# VPAC0_PAR_VPAC_VISS0_S_VBUSP_KSDW_ECC_AGGR_CFG register map
Vendor: Texas Instruments
Peripheral module from a debugger description file (folder J7ES).
Registers are 32-bit, access not given, reset 0x0 unless marked. A register's access mark holds for its fields unless they carry their own. Offsets are as the file gives them; lines under a group give offsets from that group; [hi:lo] are bit positions; {n}, {i} and the like mark numbered series; 'fields as' and 'values as' point back to an identical list; <NAME> marks a mode.

## VPAC0_PAR_VPAC_VISS0_S_VBUSP_KSDW_ECC_AGGR_CFG
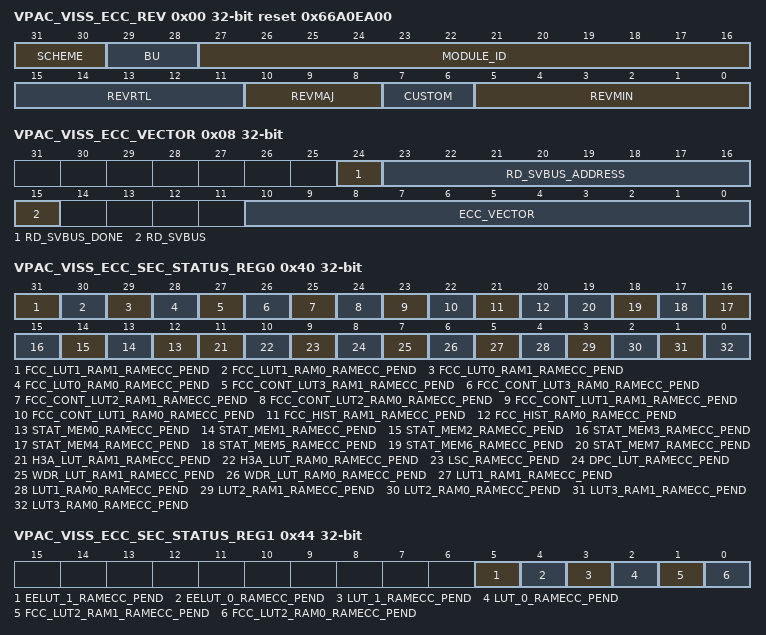
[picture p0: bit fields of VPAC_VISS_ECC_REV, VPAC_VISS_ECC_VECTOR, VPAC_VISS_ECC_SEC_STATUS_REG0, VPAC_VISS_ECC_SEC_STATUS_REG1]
0x00 VPAC_VISS_ECC_REV ro reset 0x66A0EA00 — Revision parameters
  [31:30] SCHEME
  [29:28] BU
  [27:16] MODULE_ID
  [15:11] REVRTL — RTL version
  [10:8] REVMAJ — Major version
  [7:6] CUSTOM — Custom version
  [5:0] REVMIN — Minor version
0x08 VPAC_VISS_ECC_VECTOR — ECC Register
  [24] RD_SVBUS_DONE — Status to indicate if read on serial VBUS is complete, write of any value will clear this bit. (access RW1C)
  [23:16] RD_SVBUS_ADDRESS rw — Read address
  [15] RD_SVBUS — Write 1 to trigger a read on the serial VBUS (access RW1S)
  [10:0] ECC_VECTOR rw — Value written to select the corresponding ECC RAM for control or status
0x0C VPAC_VISS_ECC_STAT ro reset 0x26 — Misc Status
  [10:0] NUM_RAMS — Indicates the number of RAMS serviced by the ECC aggregator
0x10 VPAC_VISS_ECC_RESERVED_SVBUS_y rw — Reference other documents that contain the ECC RAM wrapper and EDC controller serial vbus register sets. Offset = 1010h + (y * 4h); where y = 0h to 7h
  [31:0] DATA — Serial VBUS register data
0x3C VPAC_VISS_ECC_SEC_EOI_REG — EOI Register The EOI register is used to re-trigger the pulse interrupt signal to ensure that any nested interrupt events are serviced. The software interrupt handler must write to the EOI register at the end of the current interrupt processing routine, so that new events can re-trigger the pulse interrupt signal again. For level interrupt signals the EOI register is not functional and must not be used.
  [0] EOI_WR — EOI Register (access RW1S)
0x40 VPAC_VISS_ECC_SEC_STATUS_REG0 — Interrupt Status Register 0
  [31] FCC_LUT1_RAM1_RAMECC_PEND — Interrupt Pending Status for fcc_lut1_ram1_ramecc_pend (access RW1S)
  [30] FCC_LUT1_RAM0_RAMECC_PEND — Interrupt Pending Status for fcc_lut1_ram0_ramecc_pend (access RW1S)
  [29] FCC_LUT0_RAM1_RAMECC_PEND — Interrupt Pending Status for fcc_lut0_ram1_ramecc_pend (access RW1S)
  [28] FCC_LUT0_RAM0_RAMECC_PEND — Interrupt Pending Status for fcc_lut0_ram0_ramecc_pend (access RW1S)
  [27] FCC_CONT_LUT3_RAM1_RAMECC_PEND — Interrupt Pending Status for fcc_cont_lut3_ram1_ramecc_pend (access RW1S)
  [26] FCC_CONT_LUT3_RAM0_RAMECC_PEND — Interrupt Pending Status for fcc_cont_lut3_ram0_ramecc_pend (access RW1S)
  [25] FCC_CONT_LUT2_RAM1_RAMECC_PEND — Interrupt Pending Status for fcc_cont_lut2_ram1_ramecc_pend (access RW1S)
  [24] FCC_CONT_LUT2_RAM0_RAMECC_PEND — Interrupt Pending Status for fcc_cont_lut2_ram0_ramecc_pend (access RW1S)
  [23] FCC_CONT_LUT1_RAM1_RAMECC_PEND — Interrupt Pending Status for fcc_cont_lut1_ram1_ramecc_pend (access RW1S)
  [22] FCC_CONT_LUT1_RAM0_RAMECC_PEND — Interrupt Pending Status for fcc_cont_lut1_ram0_ramecc_pend (access RW1S)
  [21] FCC_HIST_RAM1_RAMECC_PEND — Interrupt Pending Status for fcc_hist_ram1_ramecc_pend (access RW1S)
  [20] FCC_HIST_RAM0_RAMECC_PEND — Interrupt Pending Status for fcc_hist_ram0_ramecc_pend (access RW1S)
  [n+12] STAT_MEM{n}_RAMECC_PEND (n=0..7) — Interrupt Pending Status for stat_mem{n}_ramecc_pend (access RW1S)
  [11] H3A_LUT_RAM1_RAMECC_PEND — Interrupt Pending Status for h3a_lut_ram1_ramecc_pend (access RW1S)
  [10] H3A_LUT_RAM0_RAMECC_PEND — Interrupt Pending Status for h3a_lut_ram0_ramecc_pend (access RW1S)
  [9] LSC_RAMECC_PEND — Interrupt Pending Status for lsc_ramecc_pend (access RW1S)
  [8] DPC_LUT_RAMECC_PEND — Interrupt Pending Status for dpc_lut_ramecc_pend (access RW1S)
  [7] WDR_LUT_RAM1_RAMECC_PEND — Interrupt Pending Status for wdr_lut_ram1_ramecc_pend (access RW1S)
  [6] WDR_LUT_RAM0_RAMECC_PEND — Interrupt Pending Status for wdr_lut_ram0_ramecc_pend (access RW1S)
  [5] LUT1_RAM1_RAMECC_PEND — Interrupt Pending Status for lut1_ram1_ramecc_pend (access RW1S)
  [4] LUT1_RAM0_RAMECC_PEND — Interrupt Pending Status for lut1_ram0_ramecc_pend (access RW1S)
  [3] LUT2_RAM1_RAMECC_PEND — Interrupt Pending Status for lut2_ram1_ramecc_pend (access RW1S)
  [2] LUT2_RAM0_RAMECC_PEND — Interrupt Pending Status for lut2_ram0_ramecc_pend (access RW1S)
  [1] LUT3_RAM1_RAMECC_PEND — Interrupt Pending Status for lut3_ram1_ramecc_pend (access RW1S)
  [0] LUT3_RAM0_RAMECC_PEND — Interrupt Pending Status for lut3_ram0_ramecc_pend (access RW1S)
0x44 VPAC_VISS_ECC_SEC_STATUS_REG1 — Interrupt Status Register 1
  [5] EELUT_1_RAMECC_PEND — Interrupt Pending Status for eelut_1_ramecc_pend (access RW1S)
  [4] EELUT_0_RAMECC_PEND — Interrupt Pending Status for eelut_0_ramecc_pend (access RW1S)
  [3] LUT_1_RAMECC_PEND — Interrupt Pending Status for lut_1_ramecc_pend (access RW1S)
  [2] LUT_0_RAMECC_PEND — Interrupt Pending Status for lut_0_ramecc_pend (access RW1S)
  [1] FCC_LUT2_RAM1_RAMECC_PEND — Interrupt Pending Status for fcc_lut2_ram1_ramecc_pend (access RW1S)
  [0] FCC_LUT2_RAM0_RAMECC_PEND — Interrupt Pending Status for fcc_lut2_ram0_ramecc_pend (access RW1S)
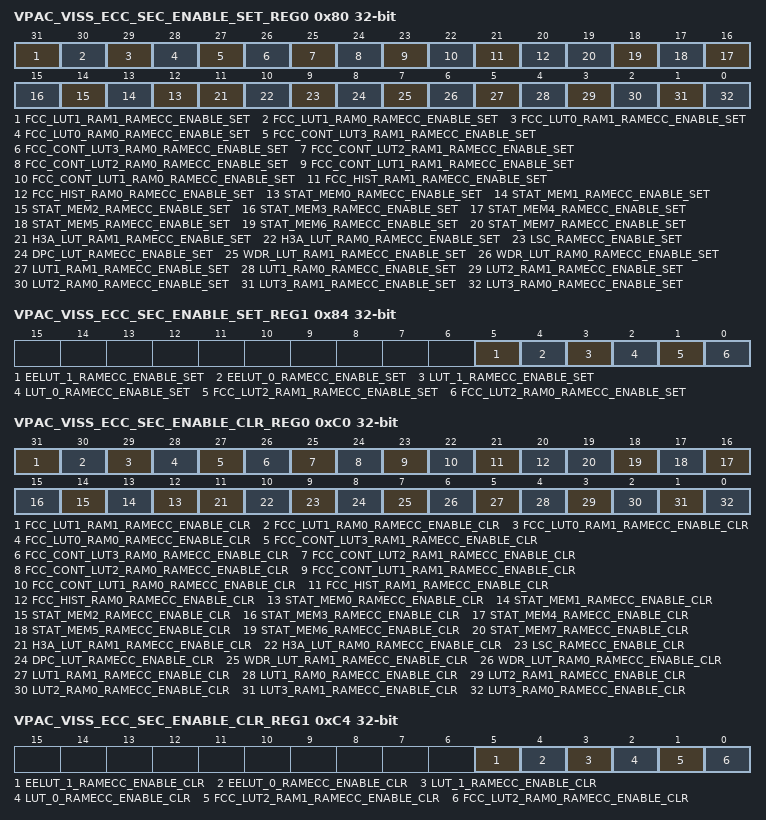
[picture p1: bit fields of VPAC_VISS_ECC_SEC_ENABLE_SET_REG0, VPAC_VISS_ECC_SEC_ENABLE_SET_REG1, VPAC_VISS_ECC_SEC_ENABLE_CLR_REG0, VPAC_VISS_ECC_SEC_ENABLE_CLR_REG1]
0x80 VPAC_VISS_ECC_SEC_ENABLE_SET_REG0 — Interrupt Enable Set Register 0
  [31] FCC_LUT1_RAM1_RAMECC_ENABLE_SET — Interrupt Enable Set Register for fcc_lut1_ram1_ramecc_pend (access RW1S)
  [30] FCC_LUT1_RAM0_RAMECC_ENABLE_SET — Interrupt Enable Set Register for fcc_lut1_ram0_ramecc_pend (access RW1S)
  [29] FCC_LUT0_RAM1_RAMECC_ENABLE_SET — Interrupt Enable Set Register for fcc_lut0_ram1_ramecc_pend (access RW1S)
  [28] FCC_LUT0_RAM0_RAMECC_ENABLE_SET — Interrupt Enable Set Register for fcc_lut0_ram0_ramecc_pend (access RW1S)
  [27] FCC_CONT_LUT3_RAM1_RAMECC_ENABLE_SET — Interrupt Enable Set Register for fcc_cont_lut3_ram1_ramecc_pend (access RW1S)
  [26] FCC_CONT_LUT3_RAM0_RAMECC_ENABLE_SET — Interrupt Enable Set Register for fcc_cont_lut3_ram0_ramecc_pend (access RW1S)
  [25] FCC_CONT_LUT2_RAM1_RAMECC_ENABLE_SET — Interrupt Enable Set Register for fcc_cont_lut2_ram1_ramecc_pend (access RW1S)
  [24] FCC_CONT_LUT2_RAM0_RAMECC_ENABLE_SET — Interrupt Enable Set Register for fcc_cont_lut2_ram0_ramecc_pend (access RW1S)
  [23] FCC_CONT_LUT1_RAM1_RAMECC_ENABLE_SET — Interrupt Enable Set Register for fcc_cont_lut1_ram1_ramecc_pend (access RW1S)
  [22] FCC_CONT_LUT1_RAM0_RAMECC_ENABLE_SET — Interrupt Enable Set Register for fcc_cont_lut1_ram0_ramecc_pend (access RW1S)
  [21] FCC_HIST_RAM1_RAMECC_ENABLE_SET — Interrupt Enable Set Register for fcc_hist_ram1_ramecc_pend (access RW1S)
  [20] FCC_HIST_RAM0_RAMECC_ENABLE_SET — Interrupt Enable Set Register for fcc_hist_ram0_ramecc_pend (access RW1S)
  [n+12] STAT_MEM{n}_RAMECC_ENABLE_SET (n=0..7) — Interrupt Enable Set Register for stat_mem{n}_ramecc_pend (access RW1S)
  [11] H3A_LUT_RAM1_RAMECC_ENABLE_SET — Interrupt Enable Set Register for h3a_lut_ram1_ramecc_pend (access RW1S)
  [10] H3A_LUT_RAM0_RAMECC_ENABLE_SET — Interrupt Enable Set Register for h3a_lut_ram0_ramecc_pend (access RW1S)
  [9] LSC_RAMECC_ENABLE_SET — Interrupt Enable Set Register for lsc_ramecc_pend (access RW1S)
  [8] DPC_LUT_RAMECC_ENABLE_SET — Interrupt Enable Set Register for dpc_lut_ramecc_pend (access RW1S)
  [7] WDR_LUT_RAM1_RAMECC_ENABLE_SET — Interrupt Enable Set Register for wdr_lut_ram1_ramecc_pend (access RW1S)
  [6] WDR_LUT_RAM0_RAMECC_ENABLE_SET — Interrupt Enable Set Register for wdr_lut_ram0_ramecc_pend (access RW1S)
  [5] LUT1_RAM1_RAMECC_ENABLE_SET — Interrupt Enable Set Register for lut1_ram1_ramecc_pend (access RW1S)
  [4] LUT1_RAM0_RAMECC_ENABLE_SET — Interrupt Enable Set Register for lut1_ram0_ramecc_pend (access RW1S)
  [3] LUT2_RAM1_RAMECC_ENABLE_SET — Interrupt Enable Set Register for lut2_ram1_ramecc_pend (access RW1S)
  [2] LUT2_RAM0_RAMECC_ENABLE_SET — Interrupt Enable Set Register for lut2_ram0_ramecc_pend (access RW1S)
  [1] LUT3_RAM1_RAMECC_ENABLE_SET — Interrupt Enable Set Register for lut3_ram1_ramecc_pend (access RW1S)
  [0] LUT3_RAM0_RAMECC_ENABLE_SET — Interrupt Enable Set Register for lut3_ram0_ramecc_pend (access RW1S)
0x84 VPAC_VISS_ECC_SEC_ENABLE_SET_REG1 — Interrupt Enable Set Register 1
  [5] EELUT_1_RAMECC_ENABLE_SET — Interrupt Enable Set Register for eelut_1_ramecc_pend (access RW1S)
  [4] EELUT_0_RAMECC_ENABLE_SET — Interrupt Enable Set Register for eelut_0_ramecc_pend (access RW1S)
  [3] LUT_1_RAMECC_ENABLE_SET — Interrupt Enable Set Register for lut_1_ramecc_pend (access RW1S)
  [2] LUT_0_RAMECC_ENABLE_SET — Interrupt Enable Set Register for lut_0_ramecc_pend (access RW1S)
  [1] FCC_LUT2_RAM1_RAMECC_ENABLE_SET — Interrupt Enable Set Register for fcc_lut2_ram1_ramecc_pend (access RW1S)
  [0] FCC_LUT2_RAM0_RAMECC_ENABLE_SET — Interrupt Enable Set Register for fcc_lut2_ram0_ramecc_pend (access RW1S)
0xC0 VPAC_VISS_ECC_SEC_ENABLE_CLR_REG0 — Interrupt Enable Clear Register 0
  [31] FCC_LUT1_RAM1_RAMECC_ENABLE_CLR — Interrupt Enable Clear Register for fcc_lut1_ram1_ramecc_pend (access RW1C)
  [30] FCC_LUT1_RAM0_RAMECC_ENABLE_CLR — Interrupt Enable Clear Register for fcc_lut1_ram0_ramecc_pend (access RW1C)
  [29] FCC_LUT0_RAM1_RAMECC_ENABLE_CLR — Interrupt Enable Clear Register for fcc_lut0_ram1_ramecc_pend (access RW1C)
  [28] FCC_LUT0_RAM0_RAMECC_ENABLE_CLR — Interrupt Enable Clear Register for fcc_lut0_ram0_ramecc_pend (access RW1C)
  [27] FCC_CONT_LUT3_RAM1_RAMECC_ENABLE_CLR — Interrupt Enable Clear Register for fcc_cont_lut3_ram1_ramecc_pend (access RW1C)
  [26] FCC_CONT_LUT3_RAM0_RAMECC_ENABLE_CLR — Interrupt Enable Clear Register for fcc_cont_lut3_ram0_ramecc_pend (access RW1C)
  [25] FCC_CONT_LUT2_RAM1_RAMECC_ENABLE_CLR — Interrupt Enable Clear Register for fcc_cont_lut2_ram1_ramecc_pend (access RW1C)
  [24] FCC_CONT_LUT2_RAM0_RAMECC_ENABLE_CLR — Interrupt Enable Clear Register for fcc_cont_lut2_ram0_ramecc_pend (access RW1C)
  [23] FCC_CONT_LUT1_RAM1_RAMECC_ENABLE_CLR — Interrupt Enable Clear Register for fcc_cont_lut1_ram1_ramecc_pend (access RW1C)
  [22] FCC_CONT_LUT1_RAM0_RAMECC_ENABLE_CLR — Interrupt Enable Clear Register for fcc_cont_lut1_ram0_ramecc_pend (access RW1C)
  [21] FCC_HIST_RAM1_RAMECC_ENABLE_CLR — Interrupt Enable Clear Register for fcc_hist_ram1_ramecc_pend (access RW1C)
  [20] FCC_HIST_RAM0_RAMECC_ENABLE_CLR — Interrupt Enable Clear Register for fcc_hist_ram0_ramecc_pend (access RW1C)
  [n+12] STAT_MEM{n}_RAMECC_ENABLE_CLR (n=0..7) — Interrupt Enable Clear Register for stat_mem{n}_ramecc_pend (access RW1C)
  [11] H3A_LUT_RAM1_RAMECC_ENABLE_CLR — Interrupt Enable Clear Register for h3a_lut_ram1_ramecc_pend (access RW1C)
  [10] H3A_LUT_RAM0_RAMECC_ENABLE_CLR — Interrupt Enable Clear Register for h3a_lut_ram0_ramecc_pend (access RW1C)
  [9] LSC_RAMECC_ENABLE_CLR — Interrupt Enable Clear Register for lsc_ramecc_pend (access RW1C)
  [8] DPC_LUT_RAMECC_ENABLE_CLR — Interrupt Enable Clear Register for dpc_lut_ramecc_pend (access RW1C)
  [7] WDR_LUT_RAM1_RAMECC_ENABLE_CLR — Interrupt Enable Clear Register for wdr_lut_ram1_ramecc_pend (access RW1C)
  [6] WDR_LUT_RAM0_RAMECC_ENABLE_CLR — Interrupt Enable Clear Register for wdr_lut_ram0_ramecc_pend (access RW1C)
  [5] LUT1_RAM1_RAMECC_ENABLE_CLR — Interrupt Enable Clear Register for lut1_ram1_ramecc_pend (access RW1C)
  [4] LUT1_RAM0_RAMECC_ENABLE_CLR — Interrupt Enable Clear Register for lut1_ram0_ramecc_pend (access RW1C)
  [3] LUT2_RAM1_RAMECC_ENABLE_CLR — Interrupt Enable Clear Register for lut2_ram1_ramecc_pend (access RW1C)
  [2] LUT2_RAM0_RAMECC_ENABLE_CLR — Interrupt Enable Clear Register for lut2_ram0_ramecc_pend (access RW1C)
  [1] LUT3_RAM1_RAMECC_ENABLE_CLR — Interrupt Enable Clear Register for lut3_ram1_ramecc_pend (access RW1C)
  [0] LUT3_RAM0_RAMECC_ENABLE_CLR — Interrupt Enable Clear Register for lut3_ram0_ramecc_pend (access RW1C)
0xC4 VPAC_VISS_ECC_SEC_ENABLE_CLR_REG1 — Interrupt Enable Clear Register 1
  [5] EELUT_1_RAMECC_ENABLE_CLR — Interrupt Enable Clear Register for eelut_1_ramecc_pend (access RW1C)
  [4] EELUT_0_RAMECC_ENABLE_CLR — Interrupt Enable Clear Register for eelut_0_ramecc_pend (access RW1C)
  [3] LUT_1_RAMECC_ENABLE_CLR — Interrupt Enable Clear Register for lut_1_ramecc_pend (access RW1C)
  [2] LUT_0_RAMECC_ENABLE_CLR — Interrupt Enable Clear Register for lut_0_ramecc_pend (access RW1C)
  [1] FCC_LUT2_RAM1_RAMECC_ENABLE_CLR — Interrupt Enable Clear Register for fcc_lut2_ram1_ramecc_pend (access RW1C)
  [0] FCC_LUT2_RAM0_RAMECC_ENABLE_CLR — Interrupt Enable Clear Register for fcc_lut2_ram0_ramecc_pend (access RW1C)
0x13C VPAC_VISS_ECC_DED_EOI_REG — EOI Register The EOI register is used to re-trigger the pulse interrupt signal to ensure that any nested interrupt events are serviced. The software interrupt handler must write to the EOI register at the end of the current interrupt processing routine, so that new events can re-trigger the pulse interrupt signal again. For level interrupt signals the EOI register is not functional and must not be used.
  [0] EOI_WR — EOI Register (access RW1S)
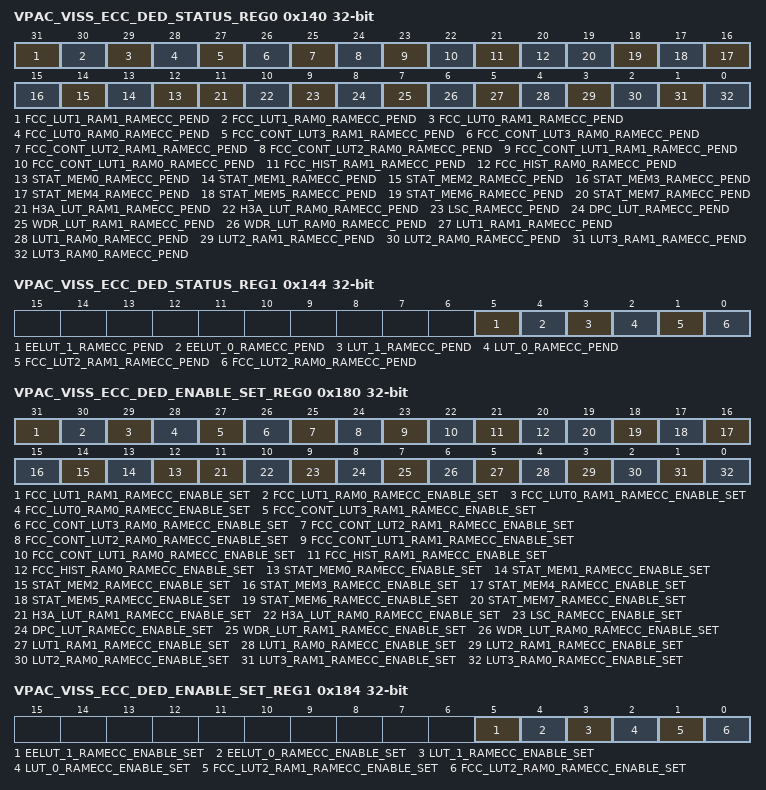
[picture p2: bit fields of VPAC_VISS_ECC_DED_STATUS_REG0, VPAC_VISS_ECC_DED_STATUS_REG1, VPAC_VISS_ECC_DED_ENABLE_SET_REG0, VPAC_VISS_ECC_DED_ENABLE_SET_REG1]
0x140 VPAC_VISS_ECC_DED_STATUS_REG0 — Interrupt Status Register 0
  fields as VPAC_VISS_ECC_SEC_STATUS_REG0
0x144 VPAC_VISS_ECC_DED_STATUS_REG1 — Interrupt Status Register 1
  fields as VPAC_VISS_ECC_SEC_STATUS_REG1
0x180 VPAC_VISS_ECC_DED_ENABLE_SET_REG0 — Interrupt Enable Set Register 0
  fields as VPAC_VISS_ECC_SEC_ENABLE_SET_REG0
0x184 VPAC_VISS_ECC_DED_ENABLE_SET_REG1 — Interrupt Enable Set Register 1
  fields as VPAC_VISS_ECC_SEC_ENABLE_SET_REG1
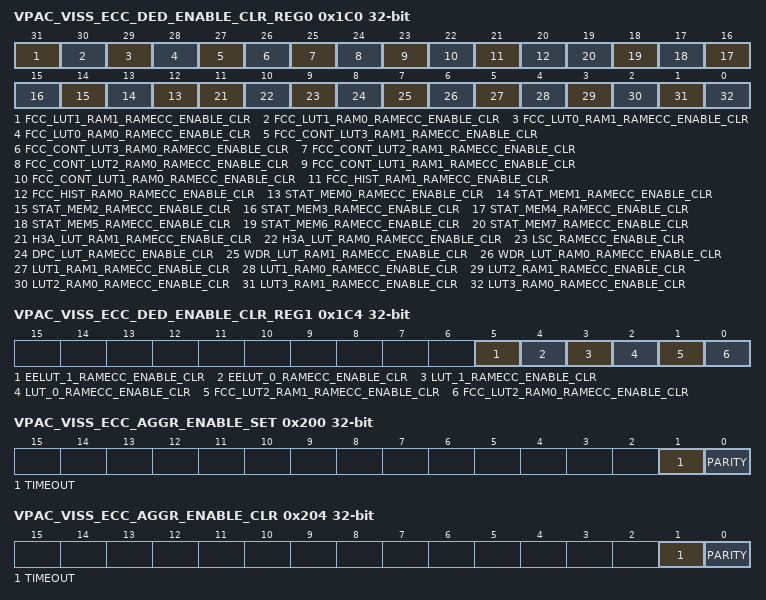
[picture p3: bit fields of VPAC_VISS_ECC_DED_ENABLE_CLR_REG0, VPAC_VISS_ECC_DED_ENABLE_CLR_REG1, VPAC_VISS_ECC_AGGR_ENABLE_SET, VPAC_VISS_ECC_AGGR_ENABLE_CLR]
0x1C0 VPAC_VISS_ECC_DED_ENABLE_CLR_REG0 — Interrupt Enable Clear Register 0
  fields as VPAC_VISS_ECC_SEC_ENABLE_CLR_REG0
0x1C4 VPAC_VISS_ECC_DED_ENABLE_CLR_REG1 — Interrupt Enable Clear Register 1
  fields as VPAC_VISS_ECC_SEC_ENABLE_CLR_REG1
0x200 VPAC_VISS_ECC_AGGR_ENABLE_SET — AGGR interrupt enable set Register
  [1] TIMEOUT — interrupt enable set for svbus timeout errors (access RW1S)
  [0] PARITY — interrupt enable set for parity errors (access RW1S)
0x204 VPAC_VISS_ECC_AGGR_ENABLE_CLR — AGGR interrupt enable clear Register
  [1] TIMEOUT — interrupt enable clear for svbus timeout errors (access RW1C)
  [0] PARITY — interrupt enable clear for parity errors (access RW1C)
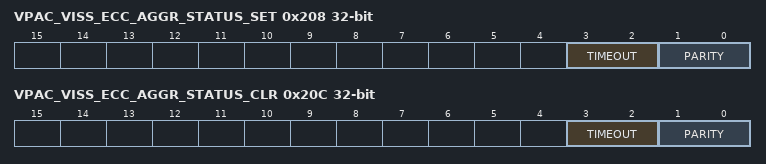
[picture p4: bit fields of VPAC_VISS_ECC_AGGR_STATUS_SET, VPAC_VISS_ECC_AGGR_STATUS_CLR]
0x208 VPAC_VISS_ECC_AGGR_STATUS_SET — AGGR interrupt status set Register
  [3:2] TIMEOUT — interrupt status set for svbus timeout errors (access RWincr)
  [1:0] PARITY — interrupt status set for parity errors (access RWincr)
0x20C VPAC_VISS_ECC_AGGR_STATUS_CLR — AGGR interrupt status clear Register
  [3:2] TIMEOUT — interrupt status clear for svbus timeout errors (access RWdecr)
  [1:0] PARITY — interrupt status clear for parity errors (access RWdecr)
